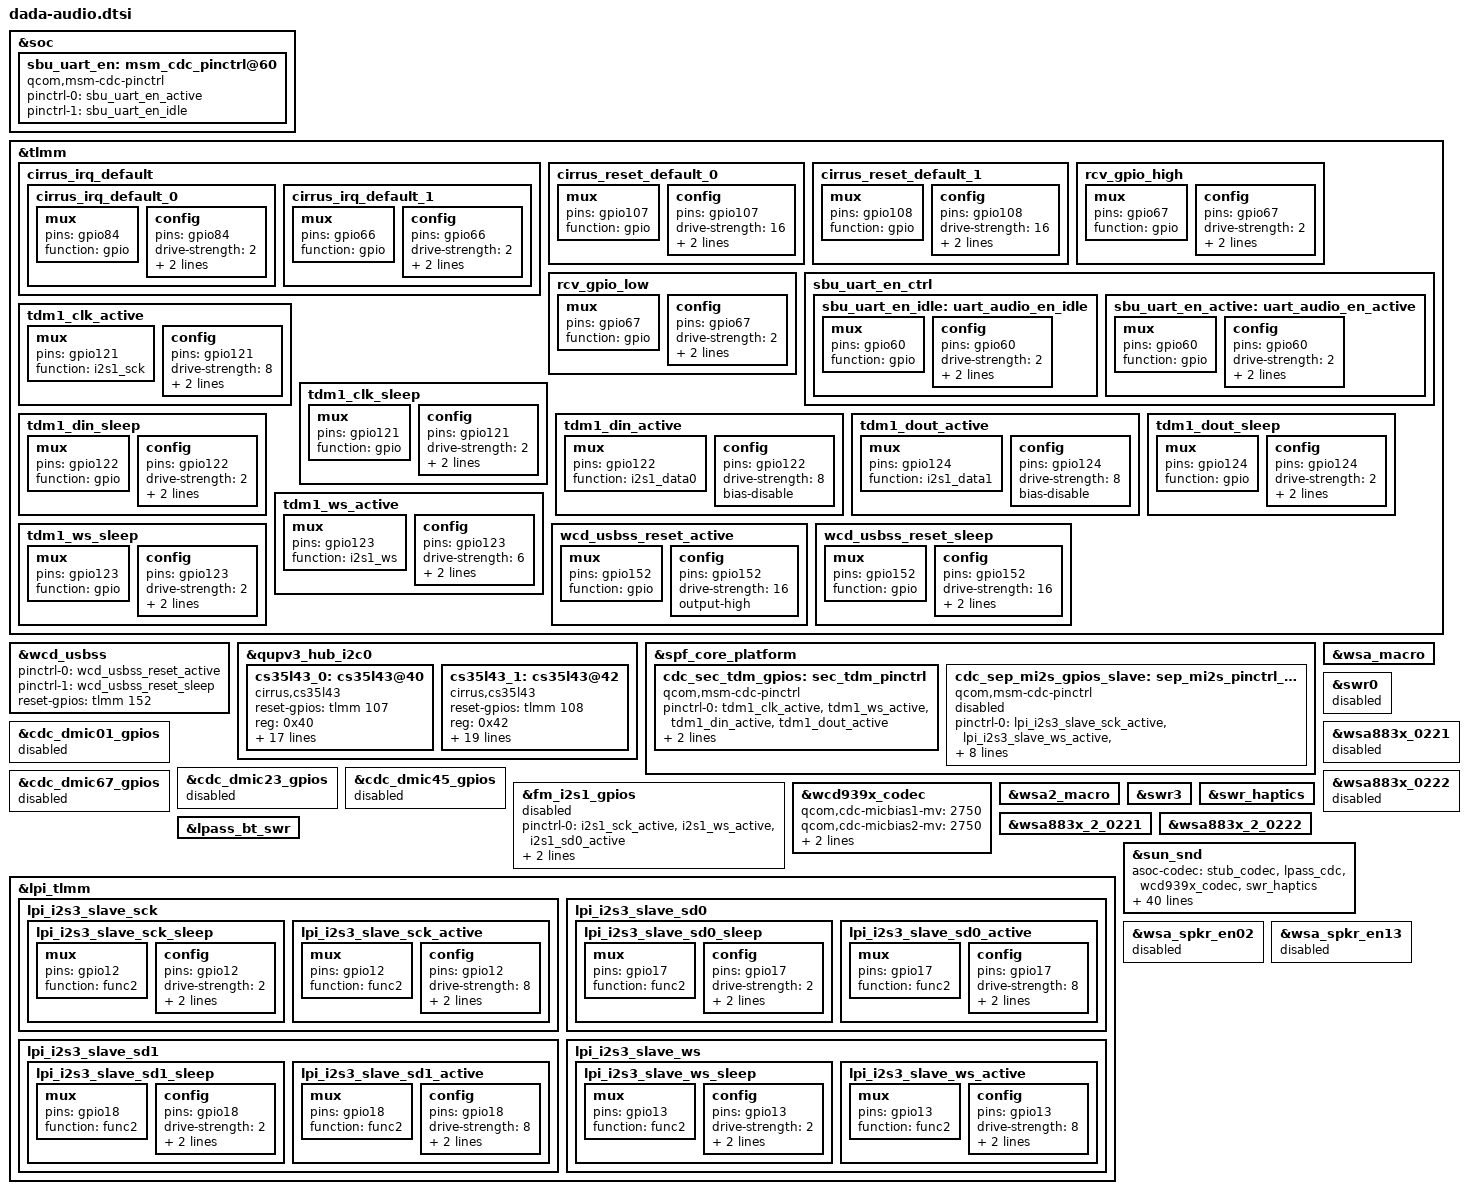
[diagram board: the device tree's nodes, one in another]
// SPDX-License-Identifier: BSD-3-Clause
/*
 * Xiaomi 15 (dada) audio: two Cirrus Logic CS35L43 smart amplifiers on
 * the I2C hub, WCD939x headset codec with the USB-C audio switch, and
 * the LPASS/sound card changes Xiaomi made on top of the QTI MTP setup.
 *
 * Xiaomi did not publish the audio devicetree for this board; this
 * follows the audio part of the stock dtbo (OS3.0.305.0).
 */

&soc {
	sbu_uart_en: msm_cdc_pinctrl@60 {
		compatible = "qcom,msm-cdc-pinctrl";
		pinctrl-names = "aud_active", "aud_sleep";
		pinctrl-0 = <&sbu_uart_en_active>;
		pinctrl-1 = <&sbu_uart_en_idle>;
		#gpio-cells = <0>;
	};
};

&tlmm {
	cirrus_irq_default {
		cirrus_irq_default_0: cirrus_irq_default_0 {
			mux {
				pins = "gpio84";
				function = "gpio";
			};

			config {
				pins = "gpio84";
				drive-strength = <2>;
				input-enable;
				bias-pull-up;
			};
		};

		cirrus_irq_default_1: cirrus_irq_default_1 {
			mux {
				pins = "gpio66";
				function = "gpio";
			};

			config {
				pins = "gpio66";
				drive-strength = <2>;
				input-enable;
				bias-pull-up;
			};
		};
	};

	cirrus_reset_default_0: cirrus_reset_default_0 {
		mux {
			pins = "gpio107";
			function = "gpio";
		};

		config {
			pins = "gpio107";
			drive-strength = <16>;
			bias-disable;
			output-high;
		};
	};

	cirrus_reset_default_1: cirrus_reset_default_1 {
		mux {
			pins = "gpio108";
			function = "gpio";
		};

		config {
			pins = "gpio108";
			drive-strength = <16>;
			bias-disable;
			output-high;
		};
	};

	rcv_gpio_high: rcv_gpio_high {
		mux {
			pins = "gpio67";
			function = "gpio";
		};

		config {
			pins = "gpio67";
			drive-strength = <2>;
			bias-pull-up;
			output-high;
		};
	};

	rcv_gpio_low: rcv_gpio_low {
		mux {
			pins = "gpio67";
			function = "gpio";
		};

		config {
			pins = "gpio67";
			drive-strength = <2>;
			bias-disable;
			output-low;
		};
	};

	sbu_uart_en_ctrl {
		sbu_uart_en_idle: uart_audio_en_idle {
			mux {
				pins = "gpio60";
				function = "gpio";
			};

			config {
				pins = "gpio60";
				drive-strength = <2>;
				bias-pull-down;
				output-low;
			};
		};

		sbu_uart_en_active: uart_audio_en_active {
			mux {
				pins = "gpio60";
				function = "gpio";
			};

			config {
				pins = "gpio60";
				drive-strength = <2>;
				bias-disable;
				output-high;
			};
		};
	};

	tdm1_clk_active: tdm1_clk_active {
		mux {
			pins = "gpio121";
			function = "i2s1_sck";
		};

		config {
			pins = "gpio121";
			drive-strength = <8>;
			bias-disable;
			output-high;
		};
	};

	tdm1_clk_sleep: tdm1_clk_sleep {
		mux {
			pins = "gpio121";
			function = "gpio";
		};

		config {
			pins = "gpio121";
			drive-strength = <2>;
			bias-pull-down;
			input-enable;
		};
	};

	tdm1_din_active: tdm1_din_active {
		mux {
			pins = "gpio122";
			function = "i2s1_data0";
		};

		config {
			pins = "gpio122";
			drive-strength = <8>;
			bias-disable;
		};
	};

	tdm1_din_sleep: tdm1_din_sleep {
		mux {
			pins = "gpio122";
			function = "gpio";
		};

		config {
			pins = "gpio122";
			drive-strength = <2>;
			bias-pull-down;
			input-enable;
		};
	};

	tdm1_dout_active: tdm1_dout_active {
		mux {
			pins = "gpio124";
			function = "i2s1_data1";
		};

		config {
			pins = "gpio124";
			drive-strength = <8>;
			bias-disable;
		};
	};

	tdm1_dout_sleep: tdm1_dout_sleep {
		mux {
			pins = "gpio124";
			function = "gpio";
		};

		config {
			pins = "gpio124";
			drive-strength = <2>;
			bias-pull-down;
			input-enable;
		};
	};

	tdm1_ws_active: tdm1_ws_active {
		mux {
			pins = "gpio123";
			function = "i2s1_ws";
		};

		config {
			pins = "gpio123";
			drive-strength = <6>;
			bias-disable;
			output-high;
		};
	};

	tdm1_ws_sleep: tdm1_ws_sleep {
		mux {
			pins = "gpio123";
			function = "gpio";
		};

		config {
			pins = "gpio123";
			drive-strength = <2>;
			bias-pull-down;
			input-enable;
		};
	};

	wcd_usbss_reset_active: wcd_usbss_reset_active {
		mux {
			pins = "gpio152";
			function = "gpio";
		};

		config {
			pins = "gpio152";
			drive-strength = <16>;
			output-high;
		};
	};

	wcd_usbss_reset_sleep: wcd_usbss_reset_sleep {
		mux {
			pins = "gpio152";
			function = "gpio";
		};

		config {
			pins = "gpio152";
			drive-strength = <16>;
			bias-disable;
			output-low;
		};
	};
};

&wcd_usbss {
	pinctrl-0 = <&wcd_usbss_reset_active>;
	pinctrl-1 = <&wcd_usbss_reset_sleep>;
	pinctrl-names = "usbss_active", "usbss_sleep";
	reset-gpios = <&tlmm 152 0>;
};

&qupv3_hub_i2c0 {
	status = "ok";

	cs35l43_0: cs35l43@40 {
		compatible = "cirrus,cs35l43";
		reset-gpios = <&tlmm 107 0>;
		reg = <0x40>;
		interrupt-parent = <&tlmm>;
		interrupts = <84 0x2008>;
		pinctrl-names = "default";
		pinctrl-0 = <&cirrus_reset_default_0 &cirrus_irq_default_0>;
		cirrus,bst-ipk-ma = <4000>;
		cirrus,asp-sdout-hiz = <3>;
		cirrus,gpio2-src-sel = <4>;
		sound-name-prefix = "B";
		cirrus,i2c-addr = <0x28>;
		cirrus,low-pwr-mode-standby = <1>;
		cirrus,vpbr-enable = <1>;
		cirrus,vpbr-rel-rate = <0>;
		cirrus,vpbr-wait = <0>;
		cirrus,vpbr-atk-rate = <0>;
		cirrus,vpbr-atk-vol = <5>;
		cirrus,vpbr-max-att = <6>;
		cirrus,vpbr-thld = <4>;
		status = "ok";
	};

	cs35l43_1: cs35l43@42 {
		compatible = "cirrus,cs35l43";
		reset-gpios = <&tlmm 108 0>;
		reg = <0x42>;
		interrupt-parent = <&tlmm>;
		interrupts = <66 0x2008>;
		pinctrl-names = "default", "rcv_gpio_high", "rcv_gpio_low";
		pinctrl-0 = <&cirrus_reset_default_1 &cirrus_irq_default_1>;
		pinctrl-1 = <&rcv_gpio_high>;
		pinctrl-2 = <&rcv_gpio_low>;
		cirrus,bst-ipk-ma = <4000>;
		cirrus,asp-sdout-hiz = <3>;
		cirrus,gpio2-src-sel = <4>;
		sound-name-prefix = "T";
		cirrus,i2c-addr = <0x2a>;
		cirrus,low-pwr-mode-standby = <1>;
		cirrus,vpbr-enable = <1>;
		cirrus,vpbr-rel-rate = <0>;
		cirrus,vpbr-wait = <0>;
		cirrus,vpbr-atk-rate = <0>;
		cirrus,vpbr-atk-vol = <5>;
		cirrus,vpbr-max-att = <6>;
		cirrus,vpbr-thld = <4>;
		status = "ok";
	};
};

&spf_core_platform {
	cdc_sec_tdm_gpios: sec_tdm_pinctrl {
		compatible = "qcom,msm-cdc-pinctrl";
		pinctrl-names = "aud_active", "aud_sleep";
		pinctrl-0 = <&tdm1_clk_active &tdm1_ws_active &tdm1_din_active &tdm1_dout_active>;
		pinctrl-1 = <&tdm1_clk_sleep &tdm1_ws_sleep &tdm1_din_sleep &tdm1_dout_sleep>;
		#gpio-cells = <0>;
		status = "ok";
	};

	cdc_sep_mi2s_gpios_slave: sep_mi2s_pinctrl_slave {
		compatible = "qcom,msm-cdc-pinctrl";
		pinctrl-names = "aud_active", "aud_sleep";
		pinctrl-0 = <&lpi_i2s3_slave_sck_active &lpi_i2s3_slave_ws_active &lpi_i2s3_slave_sd0_active &lpi_i2s3_slave_sd1_active>;
		pinctrl-1 = <&lpi_i2s3_slave_sck_sleep &lpi_i2s3_slave_ws_sleep &lpi_i2s3_slave_sd0_sleep &lpi_i2s3_slave_sd1_sleep>;
		qcom,lpi-gpios;
		qcom,tlmm-pins = <177 182>;
		#gpio-cells = <0>;
		status = "disabled";
	};
};

&cdc_dmic01_gpios {
	status = "disabled";
};

&cdc_dmic23_gpios {
	status = "disabled";
};

&cdc_dmic45_gpios {
	status = "disabled";
};

&cdc_dmic67_gpios {
	status = "disabled";
};

&fm_i2s1_gpios {
	pinctrl-0 = <&i2s1_sck_active &i2s1_ws_active &i2s1_sd0_active>;
	pinctrl-1 = <&i2s1_sck_sleep &i2s1_ws_sleep &i2s1_sd0_sleep>;
	status = "disabled";
};

&wcd939x_codec {
	qcom,cdc-micbias1-mv = <2750>;
	qcom,cdc-micbias2-mv = <2750>;
	qcom,cdc-micbias3-mv = <2750>;
	qcom,cdc-micbias4-mv = <2750>;
};

&wsa_macro {
	status = "ok";
};

&swr0 {
	status = "disabled";
};

&wsa883x_0221 {
	/delete-property/ qcom,cdc-vdd-1p8-lpm-supported;
	status = "disabled";
};

&wsa883x_0222 {
	/delete-property/ qcom,cdc-vdd-1p8-lpm-supported;
	status = "disabled";
};

&wsa2_macro {
	status = "ok";
};

&swr3 {
	status = "ok";
};

&swr_haptics {
	status = "ok";
};

&wsa883x_2_0221 {
	/delete-property/ qcom,cdc-vdd-1p8-lpm-supported;
};

&wsa883x_2_0222 {
	/delete-property/ qcom,cdc-vdd-1p8-lpm-supported;
};

&lpass_bt_swr {
	status = "ok";
};

&lpi_tlmm {
	lpi_i2s3_slave_sck {
		lpi_i2s3_slave_sck_sleep: lpi_i2s3_slave_sck_sleep {
			mux {
				pins = "gpio12";
				function = "func2";
			};

			config {
				pins = "gpio12";
				drive-strength = <2>;
				bias-pull-down;
				input-enable;
			};
		};

		lpi_i2s3_slave_sck_active: lpi_i2s3_slave_sck_active {
			mux {
				pins = "gpio12";
				function = "func2";
			};

			config {
				pins = "gpio12";
				drive-strength = <8>;
				bias-disable;
				input-enable;
			};
		};
	};

	lpi_i2s3_slave_sd0 {
		lpi_i2s3_slave_sd0_sleep: lpi_i2s3_slave_sd0_sleep {
			mux {
				pins = "gpio17";
				function = "func2";
			};

			config {
				pins = "gpio17";
				drive-strength = <2>;
				bias-pull-down;
				input-enable;
			};
		};

		lpi_i2s3_slave_sd0_active: lpi_i2s3_slave_sd0_active {
			mux {
				pins = "gpio17";
				function = "func2";
			};

			config {
				pins = "gpio17";
				drive-strength = <8>;
				bias-disable;
				input-enable;
			};
		};
	};

	lpi_i2s3_slave_sd1 {
		lpi_i2s3_slave_sd1_sleep: lpi_i2s3_slave_sd1_sleep {
			mux {
				pins = "gpio18";
				function = "func2";
			};

			config {
				pins = "gpio18";
				drive-strength = <2>;
				bias-pull-down;
				input-enable;
			};
		};

		lpi_i2s3_slave_sd1_active: lpi_i2s3_slave_sd1_active {
			mux {
				pins = "gpio18";
				function = "func2";
			};

			config {
				pins = "gpio18";
				drive-strength = <8>;
				bias-disable;
				output-high;
			};
		};
	};

	lpi_i2s3_slave_ws {
		lpi_i2s3_slave_ws_sleep: lpi_i2s3_slave_ws_sleep {
			mux {
				pins = "gpio13";
				function = "func2";
			};

			config {
				pins = "gpio13";
				drive-strength = <2>;
				bias-pull-down;
				input-enable;
			};
		};

		lpi_i2s3_slave_ws_active: lpi_i2s3_slave_ws_active {
			mux {
				pins = "gpio13";
				function = "func2";
			};

			config {
				pins = "gpio13";
				drive-strength = <8>;
				bias-disable;
				input-enable;
			};
		};
	};
};

&sun_snd {
	asoc-codec = <&stub_codec &lpass_cdc &wcd939x_codec &swr_haptics>;
	asoc-codec-names = "msm-stub-codec.1",
		"lpass-cdc",
		"wcd939x_codec",
		"swr-haptics";
	qcom,audio-routing =
		"AMIC1", "Analog Mic1",
		"AMIC1", "MIC BIAS1",
		"AMIC2", "Analog Mic2",
		"AMIC2", "MIC BIAS2",
		"AMIC3", "Analog Mic3",
		"AMIC3", "MIC BIAS4",
		"AMIC4", "Analog Mic4",
		"AMIC4", "MIC BIAS4",
		"AMIC5", "Analog Mic5",
		"AMIC5", "MIC BIAS3",
		"VA AMIC1", "Analog Mic1",
		"VA AMIC1", "VA MIC BIAS1",
		"VA AMIC2", "Analog Mic2",
		"VA AMIC2", "VA MIC BIAS2",
		"VA AMIC3", "Analog Mic3",
		"VA AMIC3", "VA MIC BIAS3",
		"VA AMIC4", "Analog Mic4",
		"VA AMIC4", "VA MIC BIAS3",
		"VA AMIC5", "Analog Mic5",
		"VA AMIC5", "VA MIC BIAS4",
		"TX DMIC0", "Digital Mic0",
		"Digital Mic0", "MIC BIAS3",
		"TX DMIC1", "Digital Mic1",
		"Digital Mic1", "MIC BIAS3",
		"TX DMIC2", "Digital Mic2",
		"Digital Mic2", "MIC BIAS1",
		"TX DMIC3", "Digital Mic3",
		"Digital Mic3", "MIC BIAS1",
		"IN1_HPHL", "HPHL_OUT",
		"IN2_HPHR", "HPHR_OUT",
		"IN3_EAR", "AUX_OUT",
		"HAP_IN", "WSA2_HAPT OUT",
		"RX_TX DEC0_INP", "TX DEC0 MUX",
		"RX_TX DEC1_INP", "TX DEC1 MUX",
		"RX_TX DEC2_INP", "TX DEC2 MUX",
		"RX_TX DEC3_INP", "TX DEC3 MUX",
		"TX SWR_INPUT", "WCD_TX_OUTPUT",
		"VA SWR_INPUT", "VA_SWR_CLK",
		"VA SWR_INPUT", "WCD_TX_OUTPUT",
		"VA_AIF1 CAP", "VA_SWR_CLK",
		"VA_AIF2 CAP", "VA_SWR_CLK",
		"VA_AIF3 CAP", "VA_SWR_CLK",
		"VA DMIC0", "Digital Mic0",
		"VA DMIC1", "Digital Mic1",
		"VA DMIC2", "Digital Mic2",
		"VA DMIC3", "Digital Mic3",
		"Digital Mic0", "VA MIC BIAS3",
		"Digital Mic1", "VA MIC BIAS3",
		"Digital Mic2", "VA MIC BIAS1",
		"Digital Mic3", "VA MIC BIAS1";
	qcom,model = "sun-mtp-snd-card";
	qcom,sec-mi2s-gpios = <&cdc_sec_tdm_gpios>;
	qcom,tdm-audio-intf = <1>;
	qcom,tdm-clk-attribute = <4 4 4 4 4 4 4 4>;
	qcom,tdm-max-slots = <2>;
	qcom,uart-audio-sw-gpio = <&sbu_uart_en>;
	/delete-property/ qcom,wcn-bt-ext;
	qcom,wsa-max-devs = <0>;
};

&wsa_spkr_en02 {
	status = "disabled";
};

&wsa_spkr_en13 {
	status = "disabled";
};
